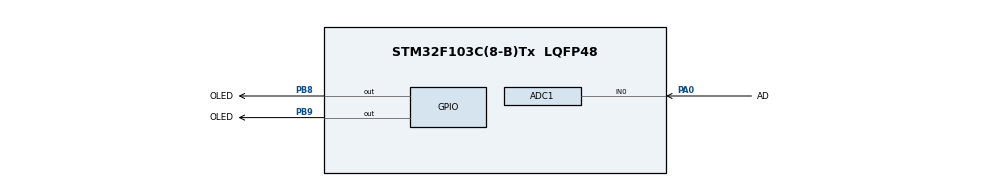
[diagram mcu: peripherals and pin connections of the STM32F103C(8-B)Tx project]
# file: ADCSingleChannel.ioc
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ADC1.Channel-0\#ChannelRegularConversion=ADC_CHANNEL_0
ADC1.NbrOfConversion=1
ADC1.NbrOfConversionFlag=1
ADC1.Rank-0\#ChannelRegularConversion=1
ADC1.SamplingTime-0\#ChannelRegularConversion=ADC_SAMPLETIME_7CYCLES_5
ADC1.master=1
Mcu.Family=STM32F1
Mcu.Name=STM32F103C(8-B)Tx
Mcu.Package=LQFP48
NVIC.PriorityGroup=NVIC_PRIORITYGROUP_4
PA0-WKUP.GPIO_Label=AD
PA0-WKUP.Signal=ADCx_IN0
PA13.Mode=Serial_Wire
PA13.Signal=SYS_JTMS-SWDIO
PA14.Mode=Serial_Wire
PA14.Signal=SYS_JTCK-SWCLK
PB8.GPIO_Label=OLED
PB8.GPIO_ModeDefaultOutputPP=GPIO_MODE_OUTPUT_OD
PB8.GPIO_PuPd=GPIO_NOPULL
PB8.Signal=GPIO_Output
PB9.GPIO_Label=OLED
PB9.GPIO_ModeDefaultOutputPP=GPIO_MODE_OUTPUT_OD
PB9.GPIO_PuPd=GPIO_NOPULL
PB9.Signal=GPIO_Output
PD0-OSC_IN.Mode=HSE-External-Oscillator
PD0-OSC_IN.Signal=RCC_OSC_IN
PD1-OSC_OUT.Mode=HSE-External-Oscillator
PD1-OSC_OUT.Signal=RCC_OSC_OUT
ProjectManager.HeapSize=0x200
ProjectManager.StackSize=0x400
ProjectManager.TargetToolchain=CMake
RCC.APB1Freq_Value=8000000
RCC.APB2Freq_Value=8000000
SH.ADCx_IN0.0=ADC1_IN0,IN0
board=custom

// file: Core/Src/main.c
/* USER CODE BEGIN Header */
/**
  ******************************************************************************
  * @file           : main.c
  * @brief          : Main program body
  ******************************************************************************
  * @attention
  *
  * Copyright (c) 2026 STMicroelectronics.
  * All rights reserved.
  *
  * This software is licensed under terms that can be found in the LICENSE file
  * in the root directory of this software component.
  * If no LICENSE file comes with this software, it is provided AS-IS.
  *
  ******************************************************************************
  */
/* USER CODE END Header */
#include "main.h"
#include "adc.h"
#include "gpio.h"

/* USER CODE BEGIN Includes */
#include "OLED.h"
#include <stdio.h>
#include <string.h>

/* USER CODE END Includes */

void SystemClock_Config(void);

/* USER CODE BEGIN 0 */
char buffer[32] = {0};
void format_voltage(float volt, char* buf, uint16_t buf_len) {
  if (buf == NULL || buf_len < 8) {
    strcpy(buf, "ERR\n");
    return;
  }
  int int_part = (int)volt;                     // 整数部分（如2.567 → 2）
  int dec_part = (int)((volt - int_part) * 1000 + 0.5); // 小数部分（如0.567→567）
  if (dec_part >= 1000) {
    int_part++;
    dec_part = 0;
  }
  snprintf(buf, buf_len, "%d.%03d", int_part, dec_part);
}
/* USER CODE END 0 */

int main(void) {

  /* MCU Configuration--------------------------------------------------------*/

  /* Reset of all peripherals, Initializes the Flash interface and the Systick. */
  HAL_Init();

  /* Configure the system clock */
  SystemClock_Config();

  /* Initialize all configured peripherals */
  MX_GPIO_Init();
  MX_ADC1_Init();
  /* USER CODE BEGIN 2 */
  OLED_Init();
  /* USER CODE END 2 */

  /* Infinite loop */
  /* USER CODE BEGIN WHILE */
  while (1) {
    // 开启ADC转换
    HAL_ADC_Start(&hadc1);
    // 等待转换 , 选择最大时间
    HAL_ADC_PollForConversion(&hadc1 , HAL_MAX_DELAY);
    // 拿到ADC的转换结果
    uint32_t adc_value = HAL_ADC_GetValue(&hadc1);
    // 转成电压输出
    float voltage = adc_value * 3.3f / 4095.0f;
    // 显示屏幕显示
    format_voltage(voltage,buffer, sizeof(buffer));
    /* USER CODE END WHILE */
    OLED_ShowString(1,1,buffer);
  }
}

void SystemClock_Config(void)
{
  RCC_OscInitTypeDef RCC_OscInitStruct = {0};
  RCC_ClkInitTypeDef RCC_ClkInitStruct = {0};
  RCC_PeriphCLKInitTypeDef PeriphClkInit = {0};

  /** Initializes the RCC Oscillators according to the specified parameters
  * in the RCC_OscInitTypeDef structure.
  */
  RCC_OscInitStruct.OscillatorType = RCC_OSCILLATORTYPE_HSI;
  RCC_OscInitStruct.HSIState = RCC_HSI_ON;
  RCC_OscInitStruct.HSICalibrationValue = RCC_HSICALIBRATION_DEFAULT;
  RCC_OscInitStruct.PLL.PLLState = RCC_PLL_NONE;
  if (HAL_RCC_OscConfig(&RCC_OscInitStruct) != HAL_OK)
  {
    Error_Handler();
  }

  /** Initializes the CPU, AHB and APB buses clocks
  */
  RCC_ClkInitStruct.ClockType = RCC_CLOCKTYPE_HCLK|RCC_CLOCKTYPE_SYSCLK
                              |RCC_CLOCKTYPE_PCLK1|RCC_CLOCKTYPE_PCLK2;
  RCC_ClkInitStruct.SYSCLKSource = RCC_SYSCLKSOURCE_HSI;
  RCC_ClkInitStruct.AHBCLKDivider = RCC_SYSCLK_DIV1;
  RCC_ClkInitStruct.APB1CLKDivider = RCC_HCLK_DIV1;
  RCC_ClkInitStruct.APB2CLKDivider = RCC_HCLK_DIV1;

  if (HAL_RCC_ClockConfig(&RCC_ClkInitStruct, FLASH_LATENCY_0) != HAL_OK)
  {
    Error_Handler();
  }
  PeriphClkInit.PeriphClockSelection = RCC_PERIPHCLK_ADC;
  PeriphClkInit.AdcClockSelection = RCC_ADCPCLK2_DIV2;
  if (HAL_RCCEx_PeriphCLKConfig(&PeriphClkInit) != HAL_OK)
  {
    Error_Handler();
  }
}

void Error_Handler(void)
{
  __disable_irq();
  while (1)
  {
  }
}
